# HK32F030xMxxA register map
Vendor: HKMicroChip Ltd.; Series: HK32F030xMxxA; File version: 0.9
CPU: CM0 r0p0, little endian, no MPU, no FPU, 3 interrupt priority bits
Registers are 32-bit, read-write, reset 0x0 unless marked. A register's access mark holds for its fields unless they carry their own. Offsets are from the block's base; [hi:lo] are bit positions.

## IWDG
Base 0x40003000
0x00 KR wo
  [15:0] KEY — Key value
0x04 PR
  [2:0] PR — Prescaler divider
0x08 RLR reset 0xFFF
  [11:0] RL — Watchdog counter reload value
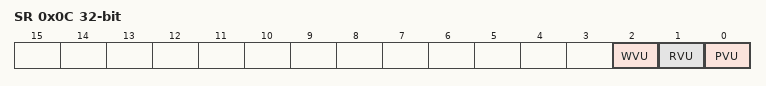
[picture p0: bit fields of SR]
0x0C SR ro
  [2] WVU — Watchdog counter window value update
  [1] RVU — Watchdog counter reload value update
  [0] PVU — Watchdog prescaler value update
0x10 WINR reset 0xFFF
  [1] WIN — Watchdog counter window value

## WWDG
Base 0x40002C00
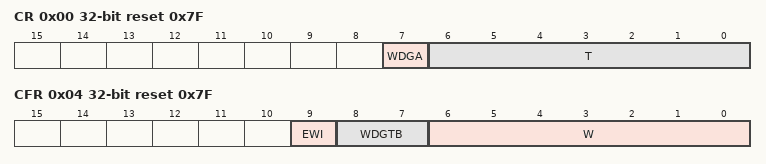
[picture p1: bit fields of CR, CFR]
0x00 CR reset 0x7F
  [7] WDGA — Activation bit
  [6:0] T — 7-bit counter, MSB to LSB
0x04 CFR reset 0x7F
  [9] EWI — Early wakeup interrupt
  [8:7] WDGTB — Timer base
  [6:0] W — 7-bit window value
0x08 SR
  [0] EWIF — Early wakeup interrupt flag

## I2C
Base 0x40005400
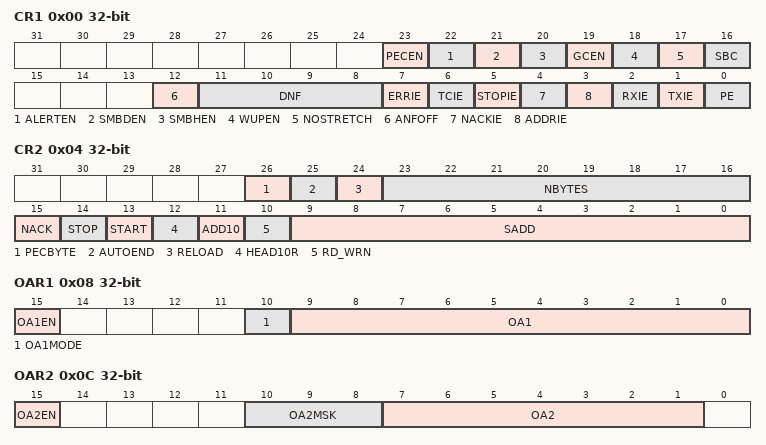
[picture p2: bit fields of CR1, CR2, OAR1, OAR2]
0x00 CR1
  [23] PECEN — PEC enable
  [22] ALERTEN — SMBus alert enable
  [21] SMBDEN — SMBus Device Default address enable
  [20] SMBHEN — SMBus Host address enable
  [19] GCEN — General call enable
  [18] WUPEN — Wakeup from Stop mode enable
  [17] NOSTRETCH — Clock stretching disable
  [16] SBC — Slave byte control
  [12] ANFOFF — Analog noise filter OFF
  [11:8] DNF — Digital noise filter
  [7] ERRIE — Error interrupts enable
  [6] TCIE — Transfer Complete interrupt enable
  [5] STOPIE — STOP detection Interrupt enable
  [4] NACKIE — Not acknowledge received Interrupt enable
  [3] ADDRIE — Address match Interrupt enable (slave only)
  [2] RXIE — RX Interrupt enable
  [1] TXIE — TX Interrupt enable
  [0] PE — Peripheral enable
0x04 CR2 access not given
  [26] PECBYTE rw — Packet error checking byte
  [25] AUTOEND rw — Automatic end mode (master mode)
  [24] RELOAD rw — NBYTES reload mode
  [23:16] NBYTES rw — Number of bytes
  [15] NACK rw — NACK generation (slave mode)
  [14] STOP rw — STOP generation (master mode)
  [13] START rw — Start generation
  [12] HEAD10R rw — 10-bit address header only read direction (master receiver mode)
  [11] ADD10 rw — 10-bit addressing mode (master mode)
  [10] RD_WRN rw — Transfer direction (master mode)
  [9:0] SADD
0x08 OAR1
  [15] OA1EN — Own Address 1 enable
  [10] OA1MODE — Own Address 1 10-bit mode
  [9:0] OA1
0x0C OAR2
  [15] OA2EN — Own Address 2 enable
  [10:8] OA2MSK — Own Address 2 masks
  [7:1] OA2 — Interface address
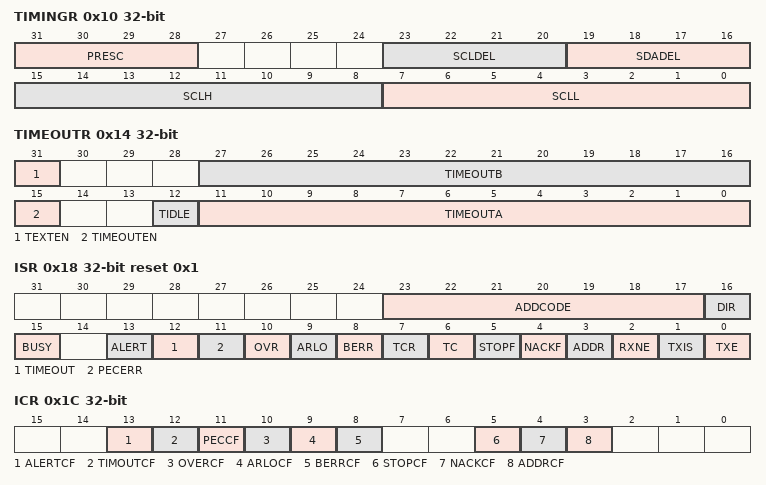
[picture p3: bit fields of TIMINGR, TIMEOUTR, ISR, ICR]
0x10 TIMINGR
  [31:28] PRESC — Timing prescaler
  [23:20] SCLDEL — Data setup time
  [19:16] SDADEL — Data hold time
  [15:8] SCLH — SCL high period (master mode)
  [7:0] SCLL — SCL low period (master mode)
0x14 TIMEOUTR
  [31] TEXTEN — Extended clock timeout enable
  [27:16] TIMEOUTB — Bus timeout B
  [15] TIMEOUTEN — Clock timeout enable
  [12] TIDLE — Idle clock timeout detection
  [11:0] TIMEOUTA — Bus Timeout A
0x18 ISR access per field reset 0x1
  [23:17] ADDCODE ro — Address match code (Slave mode)
  [16] DIR ro — Transfer direction (Slave mode)
  [15] BUSY ro — Bus busy
  [13] ALERT ro — SMBus alert
  [12] TIMEOUT ro — Timeout or tLOW detection flag
  [11] PECERR ro — PEC Error in reception
  [10] OVR ro — Overrun/Underrun (slave mode)
  [9] ARLO ro — Arbitration lost
  [8] BERR ro — Bus error
  [7] TCR ro — Transfer Complete Reload
  [6] TC ro — Transfer Complete (master mode)
  [5] STOPF ro — STOP detection flag
  [4] NACKF ro — Not Acknowledge received flag
  [3] ADDR ro — Address matched (slave mode)
  [2] RXNE ro — Receive data register not empty (receivers)
  [1] TXIS rw — Transmit interrupt status (transmitters)
  [0] TXE rw — Transmit data register empty (transmitters)
0x1C ICR wo
  [13] ALERTCF — Alert flag clear
  [12] TIMOUTCF — Timeout detection flag clear
  [11] PECCF — PEC Error flag clear
  [10] OVERCF — Overrun/Underrun flag clear
  [9] ARLOCF — Arbitration Lost flag clear
  [8] BERRCF — Bus error flag clear
  [5] STOPCF — STOP detection flag clear
  [4] NACKCF — Not Acknowledge flag clear
  [3] ADDRCF — Address matched flag clear
0x20 PECR ro
  [7:0] PEC — Packet error checking register
0x24 RXDR ro
  [7:0] RXDATA — 8-bit receive data
0x28 TXDR
  [7:0] TXDATA — 8-bit transmit data

## SPI
Base 0x40013000
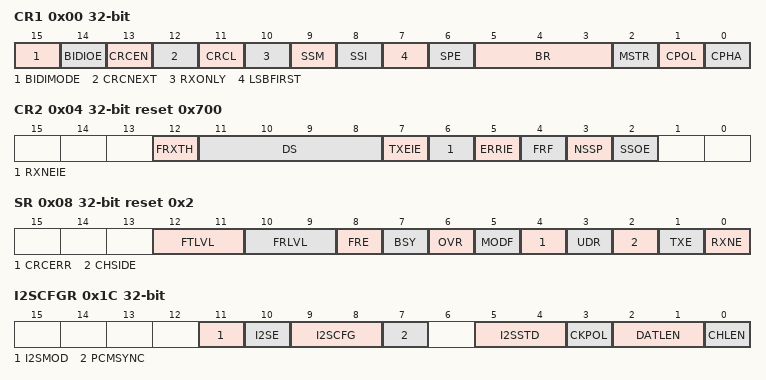
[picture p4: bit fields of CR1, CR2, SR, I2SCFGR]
0x00 CR1
  [15] BIDIMODE — Bidirectional data mode enable
  [14] BIDIOE — Output enable in bidirectional mode
  [13] CRCEN — Hardware CRC calculation enable
  [12] CRCNEXT — Transmit CRC next
  [11] CRCL — CRC length
  [10] RXONLY — Receive only mode enabled
  [9] SSM — Software slave management
  [8] SSI — Internal slave select
  [7] LSBFIRST — Frame format
  [6] SPE — SPI enable
  [5:3] BR — Baud rate control
  [2] MSTR — Master selection
  [1] CPOL — Clock polarity
  [0] CPHA — Clock phase
0x04 CR2 reset 0x700
  [12] FRXTH — FIFO reception threshold
  [11:8] DS — Data size
  [7] TXEIE — Tx buffer empty interrupt enable
  [6] RXNEIE — RX buffer not empty interrupt enable
  [5] ERRIE — Error interrupt enable
  [4] FRF — Frame format
  [3] NSSP — NSS pulse management
  [2] SSOE — SS output enable
0x08 SR access per field reset 0x2
  [12:11] FTLVL ro — FIFO Transmission Level
  [10:9] FRLVL ro — FIFO reception level
  [8] FRE ro — Frame format error
  [7] BSY ro — Busy flag
  [6] OVR ro — Overrun flag
  [5] MODF ro — Mode fault
  [4] CRCERR rw — CRC error flag
  [3] UDR ro — Underrun flag
  [2] CHSIDE ro — Channel side
  [1] TXE ro — Transmit buffer empty
  [0] RXNE ro — Receive buffer not empty
0x0C DR
  [15:0] DR — Data register
0x10 CRCPR reset 0x7
  [15:0] CRCPOLY — CRC polynomial register
0x14 RXCRCR ro
  [15:0] RXCRC
0x18 TXCRCR ro
  [15:0] TXCRC
0x1C I2SCFGR
  [11] I2SMOD — I2S mode selection
  [10] I2SE — I2S enable
  [9:8] I2SCFG — I2S configuration mode
  [7] PCMSYNC — PCM frame synchronization
  [5:4] I2SSTD — I2S standard selection
  [3] CKPOL — Inactive state clock polarity
  [2:1] DATLEN — Data length to be transferred
  [0] CHLEN — Channel length (number of bits per audio channel
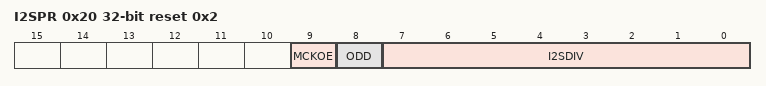
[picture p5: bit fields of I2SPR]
0x20 I2SPR reset 0x2
  [9] MCKOE — Master clock output enable
  [8] ODD — Odd factor for the prescaler
  [7:0] I2SDIV — I2S linear prescaler

## BEEP
Base 0x40007C00
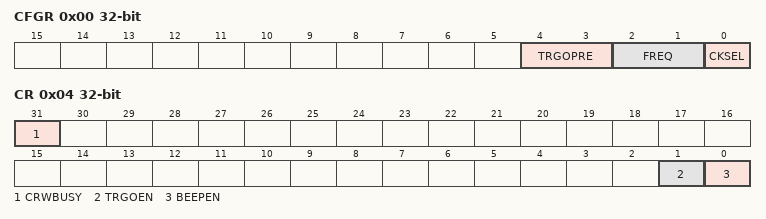
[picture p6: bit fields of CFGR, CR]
0x00 CFGR
  [4:3] TRGOPRE — Prescale clock of the TRGO signal
  [2:1] FREQ — Prescale clock source of the Beeper
  [0] CKSEL — Timing clock of the Beeper
0x04 CR access per field
  [31] CRWBUSY ro — The BEEP_CR register is written by the APB bus
  [1] TRGOEN rw — The TRGO output enable
  [0] BEEPEN rw — The beeper enable

## DBGMCU
Base 0x40015800
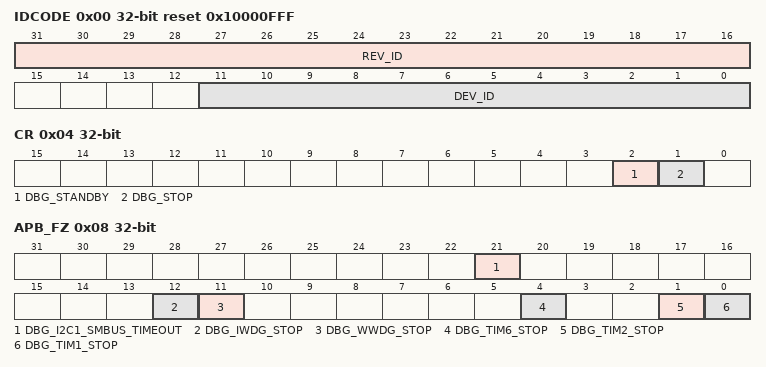
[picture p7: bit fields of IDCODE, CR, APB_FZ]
0x00 IDCODE ro reset 0x10000FFF
  [31:16] REV_ID — Revision identifier
  [11:0] DEV_ID — Device identifier
0x04 CR
  [2] DBG_STANDBY — Debug Standby mode
  [1] DBG_STOP — Debug Stop mode
0x08 APB_FZ
  [21] DBG_I2C1_SMBUS_TIMEOUT — SMBUS tiomout mode stopped when core is halted
  [12] DBG_IWDG_STOP — Debug independent watchdog stopped when core is halted
  [11] DBG_WWDG_STOP — Debug window watchdog stopped when core is halte
  [4] DBG_TIM6_STOP — TIM6 counter stopped when core is halted
  [1] DBG_TIM2_STOP — TIM2 counter stopped when core is halted
  [0] DBG_TIM1_STOP — TIM1 counter stopped when core is halted
